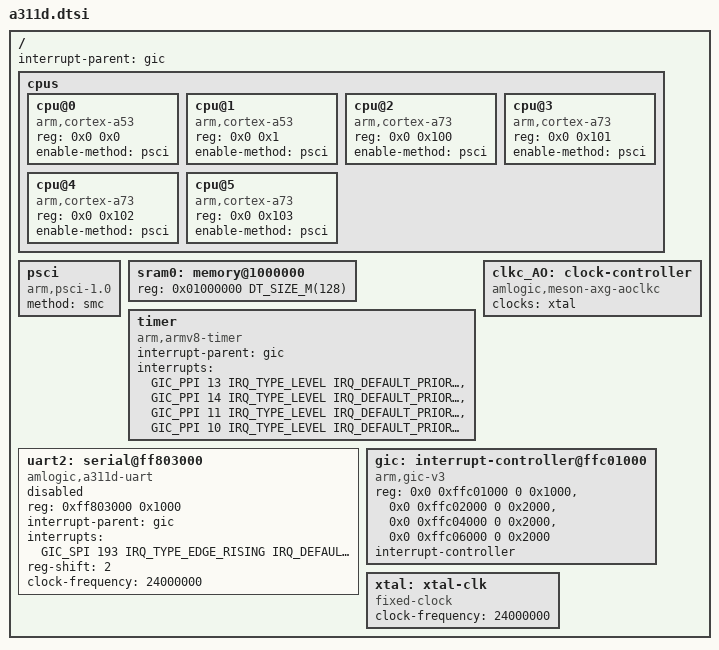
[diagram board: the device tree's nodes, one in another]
/*
 * Copyright 2023 Synaptics
 * 
 * Author: Shiv
 */

#include <arm64/armv8-a.dtsi>
#include <zephyr/dt-bindings/interrupt-controller/arm-gic.h>
#include <zephyr/dt-bindings/interrupt-controller/irq.h>
#include <zephyr/dt-bindings/clock/g12a-clkc.h>
#include <zephyr/dt-bindings/clock/g12a-aoclkc.h>
#include <mem.h>


/ {
	interrupt-parent = <&gic>;
	#address-cells = <1>;
	#size-cells = <1>;

	cpus {
		#address-cells = <2>;
		#size-cells = <0>;

		cpu@0 {
			device_type = "cpu";
			compatible = "arm,cortex-a53";
			reg = <0x0 0x0>;
			enable-method = "psci";
		};
		cpu@1 {
			device_type = "cpu";
			compatible = "arm,cortex-a53";
			reg = <0x0 0x1>;
			enable-method = "psci";
		};
		cpu@2 {
			device_type = "cpu";
			compatible = "arm,cortex-a73";
			reg = <0x0 0x100>;
			enable-method = "psci";
		};
		cpu@3 {
			device_type = "cpu";
			compatible = "arm,cortex-a73";
			reg = <0x0 0x101>;
			enable-method = "psci";
		};
		cpu@4 {
			device_type = "cpu";
			compatible = "arm,cortex-a73";
			reg = <0x0 0x102>;
			enable-method = "psci";
		};
		cpu@5 {
			device_type = "cpu";
			compatible = "arm,cortex-a73";
			reg = <0x0 0x103>;
			enable-method = "psci";
		};
        
	};

	psci: psci {
		compatible = "arm,psci-1.0";
		method = "smc";
	};

	sram0: memory@1000000 {
		reg = <0x01000000 DT_SIZE_M(128)>;
	};

	timer {
		compatible = "arm,armv8-timer";
		interrupt-parent = <&gic>;
		interrupts = <GIC_PPI 13 IRQ_TYPE_LEVEL IRQ_DEFAULT_PRIORITY>,
			         <GIC_PPI 14 IRQ_TYPE_LEVEL IRQ_DEFAULT_PRIORITY>,
			         <GIC_PPI 11 IRQ_TYPE_LEVEL IRQ_DEFAULT_PRIORITY>,
			         <GIC_PPI 10 IRQ_TYPE_LEVEL IRQ_DEFAULT_PRIORITY>;
                    };

    // clkc: clock-controller {
    //     compatible = "amlogic,g12a-clkc";
    //     #clock-cells = <1>;
    //     clocks = <&xtal>;
    //     clock-names = "xtal";
    // };

//---------------------working------------------------------//
	uart2: serial@ff803000 {
		compatible = "amlogic,a311d-uart", "ns16550";
		reg = <0xff803000 0x1000>;
		interrupt-parent = <&gic>;
		interrupts = <GIC_SPI 193 IRQ_TYPE_EDGE_RISING IRQ_DEFAULT_PRIORITY>;
	// 		clocks = <&xtal>, <&clkc_AO CLKID_AO_UART>, <&xtal>;
		status = "disabled";
		reg-shift = <2>;
		clock-frequency = <24000000>;
	};

	clkc_AO: clock-controller {
		compatible = "amlogic,meson-axg-aoclkc";
		#clock-cells = <1>;
		#reset-cells = <1>;
		clocks = <&xtal>;
		clock-names = "xtal";
	};

	gic: interrupt-controller@ffc01000 {
		compatible = "arm,gic-v3", "arm,gic";
		reg = <0x0 0xffc01000 0 0x1000>,
				<0x0 0xffc02000 0 0x2000>,
				<0x0 0xffc04000 0 0x2000>,
				<0x0 0xffc06000 0 0x2000>;
		interrupt-controller;
		#interrupt-cells = <4>;
		#address-cells = <0>;
		#clock-cells = <0>;
	};

//------------------------------------------------------------//

	// soc {
	// 	compatible = "simple-bus";
	// 	#address-cells = <2>;
	// 	#size-cells = <2>;
	// 	ranges;

	// 	apb: bus@ff600000 {
	// 		compatible = "simple-bus";
	// 		reg = <0x0 0xff600000 0x0 0x200000>;
	// 		#address-cells = <2>;
	// 		#size-cells = <2>;
	// 		ranges = <0x0 0x0 0x0 0xff600000 0x0 0x200000>;

	// 		hiu: bus@3c000 {
	// 			compatible = "simple-bus";
	// 			reg = <0x0 0x3c000 0x0 0x1400>;
	// 			#address-cells = <2>;
	// 			#size-cells = <2>;
	// 			ranges = <0x0 0x0 0x0 0x3c000 0x0 0x1400>;

	// 			hhi: system-controller@0 {
	// 				compatible = "amlogic,meson-gx-hhi-sysctrl",
	// 						 "simple-mfd", "syscon";
	// 				reg = <0 0 0 0x400>;

	// 				clkc: clock-controller {
	// 					compatible = "amlogic,g12a-clkc";
	// 					#clock-cells =<0>;
	// 					clocks = <&xtal>;
	// 					clock-names = "xtal";
	// 				};

	// 			};
	// 		};
	// 	};

	// 	gic: interrupt-controller@ffc01000 {
	// 		compatible = "arm,gic-v3", "arm,gic";
	// 		reg = <0x0 0xffc01000 0 0x1000>,
	// 			  <0x0 0xffc02000 0 0x2000>,
	// 			  <0x0 0xffc04000 0 0x2000>,
	// 			  <0x0 0xffc06000 0 0x2000>;
	// 		interrupt-controller;
	// 		#interrupt-cells = <4>;
	// 		#address-cells = <0>;
	// 		#clock-cells = <0>;
	// 	};

	// 	aobus: bus@ff800000 {
	// 		compatible = "simple-bus";
	// 		reg = <0x0 0xff800000 0x0 0x100000>;
	// 		#address-cells = <2>;
	// 		#size-cells = <2>;
	// 		ranges = <0x0 0x0 0x0 0xff800000 0x0 0x100000>;

	// 		sysctrl_AO: sys-ctrl@0 {
	// 			compatible = "amlogic,meson-gx-ao-sysctrl",
	// 					"simple-mfd", "syscon";
	// 			reg = <0x0 0x0 0x0 0x100>;
	// 			#address-cells = <2>;
	// 			#size-cells = <2>;
	// 			ranges = <0x0 0x0 0x0 0x0 0x0 0x100>;

	// 			clkc_AO: clock-controller {
	// 				compatible = "amlogic,meson-axg-aoclkc";
	// 				#clock-cells = <0>;
	// 				#reset-cells = <1>;
	// 				clocks = <&xtal>, <&clkc CLKID_CLK81>;
	// 				clock-names = "xtal", "mpeg-clk", "abc";
	// 			};

				// pinctrl_aobus: pinctrl@14 {
				// 	compatible = "amlogic,meson-axg-aobus-pinctrl";
				// 	#address-cells = <2>;
				// 	#size-cells = <2>;
				// 	#clock-cells = <0>;
				// 	ranges;

				// 	gpio_ao: bank@14 {
				// 		reg = <0x0 0x00014 0x0 0x8>,
				// 			  <0x0 0x0002c 0x0 0x4>,
				// 			  <0x0 0x00024 0x0 0x8>;
				// 		reg-names = "mux", "pull", "gpio";
				// 		gpio-controller;
				// 		#gpio-cells = <2>;
				// 		gpio-ranges = <&pinctrl_aobus 0 0 15>;
				// 		#clock-cells = <0>;
				// 	};

				// 	uart_ao_a_pins: uart-a-ao {
				// 		mux {
				// 			groups = "uart_ao_a_tx",
				// 				"uart_ao_a_rx";
				// 			function = "uart_ao_a";
				// 			bias-disable;
				// 		};
				// 	};

				// 	uart_ao_a_cts_rts_pins: uart-ao-a-cts-rts {
				// 		mux {
				// 			groups = "uart_ao_a_cts",
				// 				"uart_ao_a_rts";
				// 			function = "uart_ao_a";
				// 			bias-disable;
				// 		};
				// 	};
				// };
		// 	};
		// };

	// 	uart2: serial@3000 {
	// 		compatible = "amlogic,meson-ao-uart","ns16550";
	// 		reg = <0x0 0x3000 0x0 0x18>;
	// 		interrupts = <GIC_SPI 193 IRQ_TYPE_EDGE_RISING IRQ_DEFAULT_PRIORITY>;
	// 		clocks = <&xtal>, <&clkc_AO CLKID_AO_UART>, <&xtal>;
	// 		clock-names = "xtal", "pclk", "baud", "test";
	// 		status = "disabled";
	// 	};
	// };

	// soc {
	// 	compatible = "simple-bus";
	// 	#address-cells = <2>;
	// 	#size-cells = <2>;

	// 	// apb: bus@ff600000 {
	// 	// 	compatible = "simple-bus";
	// 	// 	reg = <0x0 0xff600000 0x0 0x200000>;
	// 	// 	#address-cells = <2>;
	// 	// 	#size-cells = <2>;
	// 	// 	ranges = <0x0 0x0 0x0 0xff600000 0x0 0x200000>;

	// 	// 	hiu: bus@3c000 {
	// 	// 		compatible = "simple-bus";
	// 	// 		reg = <0x0 0x3c000 0x0 0x1400>;
	// 	// 		#address-cells = <2>;
	// 	// 		#size-cells = <2>;
	// 	// 		ranges = <0x0 0x0 0x0 0x3c000 0x0 0x1400>;

	// 	// 		hhi: system-controller@0 {
	// 	// 			compatible = "amlogic,meson-gx-hhi-sysctrl",
	// 	// 					 "simple-mfd", "syscon";
	// 	// 			reg = <0 0 0 0x400>;

	// 	// 			clkc: clock-controller {
	// 	// 				compatible = "amlogic,g12a-clkc";
	// 	// 				#clock-cells =<0>;
	// 	// 				clocks = <&xtal>;
	// 	// 				clock-names = "xtal";
	// 	// 			};

	// 	// 		};
	// 	// 	};
	// 	// };

	// 	uart2: serial@ff803000 {
	// 		compatible = "amlogic,meson-ao-uart","ns16550";
	// 		reg = < 0x0 0xff803000 0x0 0x1000>;
	// 		interrupt-parent = <&gic>;
	// 		interrupts = <GIC_SPI 193 IRQ_TYPE_EDGE_RISING IRQ_DEFAULT_PRIORITY>;
	// 		//clocks = <&xtal>, <&clkc_AO CLKID_AO_UART>, <&xtal>;
	// 		reg-shift = <2>;
	// 		clock-frequency = <24000000>;
	// 		//clock-names = "xtal", "pclk", "baud", "test";
	// 		status = "disabled";
	// 	};
		

	// 	gic: interrupt-controller@ffc01000 {
	// 		compatible = "arm,gic-v3", "arm,gic";
	// 		reg = <0x0 0xffc01000 0 0x1000>,
	// 			  <0x0 0xffc02000 0 0x2000>,
	// 			  <0x0 0xffc04000 0 0x2000>,
	// 			  <0x0 0xffc06000 0 0x2000>;
	// 		interrupt-controller;
	// 		#interrupt-cells = <4>;
	// 		#address-cells = <0>;
	// 		#clock-cells = <0>;
	// 	};
	// };

	// clkc_AO: clock-controller {
	// 	compatible = "amlogic,meson-axg-aoclkc";
	// 	#clock-cells = <1>;
	// 	#reset-cells = <1>;
	// 	clocks = <&xtal>;
	// 	clock-names = "xtal";
	// };

	xtal: xtal-clk {
		compatible = "fixed-clock";
		clock-frequency = <24000000>;
		//clock-output-names = "xtal";
		#clock-cells = <0>;
	};
};
